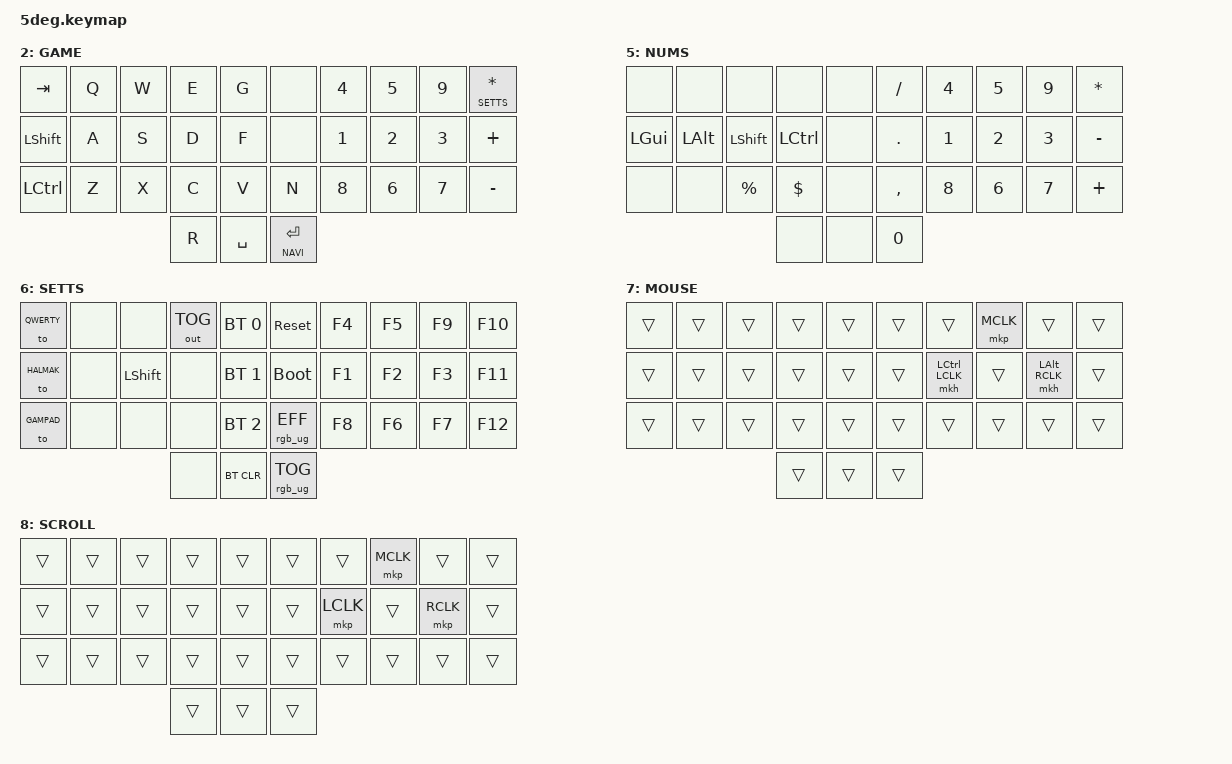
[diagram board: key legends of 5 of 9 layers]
/*
 * 5deg keymap — ported from little-wing
 *
 * Layers:
 *   0 = HALMAK (default)
 *   1 = QWERTY
 *   2 = GAMPAD
 *   3 = NAVI   (symbols + navigation)
 *   4 = EDIT   (undo/cut/copy/paste, brackets, alt-tab)
 *   5 = NUMS   (numpad grid)
 *   6 = SETTS  (layout select, BT, F-keys, system)
 *   7 = ALTAB  (alt-tab hold mode)
 *   8 = MOUSE  (auto-activated by trackball, mouse clicks)
 *   9 = SCROLL (trackball → scroll wheel)
 *
 * Home-row mods use QWERTY_MOD_MACRO so that holding a mod on
 * the HALMAK layer sends shortcuts in QWERTY positions (Ctrl+C etc).
 *
 * Key positions:
 *
 * LEFT (pinky → inner)         RIGHT (inner → pinky)
 * ┌────┬────┬────┬────┬────┐   ┌────┬────┬────┬────┬────┐
 * │ 0  │ 1  │ 2  │ 3  │ 4  │   │ 5  │ 6  │ 7  │ 8  │ 9  │
 * ├────┼────┼────┼────┼────┤   ├────┼────┼────┼────┼────┤
 * │ 10 │ 11 │ 12 │ 13 │ 14 │   │ 15 │ 16 │ 17 │ 18 │ 19 │
 * ├────┼────┼────┼────┼────┤   ├────┼────┼────┼────┼────┤
 * │ 20 │ 21 │ 22 │ 23 │ 24 │   │ 25 │ 26 │ 27 │ 28 │ 29 │
 * └────┴────┴──┬─┴──┬─┴────┘   └────┴─┬──┴────┴────┴────┘
 *              │ 30 │ 31 │        │ 32 │
 *              └────┴────┘        └────┘
 */

#include <behaviors.dtsi>
#include <dt-bindings/zmk/keys.h>
#include <dt-bindings/zmk/bt.h>
#include <dt-bindings/zmk/outputs.h>
#include <dt-bindings/zmk/mouse.h>
#include <dt-bindings/zmk/input_transform.h>
#include <dt-bindings/zmk/rgb.h>
#include <dt-bindings/zmk/ext_power.h>

&lt {
	flavor = "hold-preferred";
    tapping-term-ms = <200>;
    quick-tap-ms = <100>;
    require-prior-idle-ms = <150>;
};

/* Per-hand position lists for hold-trigger-key-positions on home-row mods.
 * A home-row mod only resolves to HOLD when an OPPOSITE-hand key triggers it,
 * which eliminates same-hand rolling misfires (e.g. typing "th" briefly
 * sharing two HRM keys on the left should never fire a modifier). */
#define LEFT_HAND  0 1 2 3 4 10 11 12 13 14 20 21 22 23 24 30 31
#define RIGHT_HAND 5 6 7 8 9 15 16 17 18 19 25 26 27 28 29 32
#define RIGHT_HAND_CTRL  5 6 7 8 9 15 16 17 18 19 25 26 27 28 29 32 /* one handed ctrl-q ctrl-a ctrl-s */ 0 10 11 

/* Per-finger HRM tapping terms (ms). Tuned from typing-hold-time
 * distribution: ~1.4-1.6× the p95 typing hold per finger so normal
 * typing rarely trips the hold-timer but chord still feels responsive.
 * Pinky drags more, so longer term; index is fastest, shortest term. */
#define HRM_TERM_PINKY  220
#define HRM_TERM_RING   200
#define HRM_TERM_MIDDLE 160   /* used by sht — can move independently */
#define HRM_TERM_INDEX  180

/* Quick-tap window: same across fingers per the retap data — slower
 * fingers don't double-tap faster, they just double-tap less often. */
#define HRM_QUICK_TAP   120

&caps_word {
	continue-list = <UNDER MINUS BSPC RSHFT LSHFT>;
};

#define HALMAK 0
#define QWERTY 1
#define GAMPAD 2
#define NAVI   3
#define EDIT   4
#define NUMS   5
#define SETTS  6
#define MOUSE  7
#define SCROLL 8

/* Home-row mod macro: hold activates QWERTY layer + modifier
 * so that keyboard shortcuts (Ctrl+C etc) use QWERTY positions
 * even when typing in HALMAK. */
#define QWERTY_MOD_MACRO(name, mod)            \
name: name##_macro {                           \
	compatible = "zmk,behavior-macro";         \
	#binding-cells = <0>;                      \
	wait-ms = <0>;                             \
    bindings                                   \
        = <&macro_press &mo QWERTY &kp mod>    \
        , <&macro_pause_for_release>           \
        , <&macro_release &mo QWERTY &kp mod>; \
};

/ {
    macros {
        QWERTY_MOD_MACRO(qalt, LALT)
        QWERTY_MOD_MACRO(qgui, LGUI)
        QWERTY_MOD_MACRO(qctl, LCTRL)

    };
};

#define HOME_ROW_MOD_TAP(name, macro, OPP_HAND, TERM) \
name: name##_mod_tap {                                \
    compatible = "zmk,behavior-hold-tap";             \
    #binding-cells = <2>;                             \
    flavor = "tap-preferred";                         \
    tapping-term-ms = <TERM>;                         \
    quick-tap-ms = <HRM_QUICK_TAP>;                   \
    hold-trigger-key-positions = <OPP_HAND>;          \
    require-prior-idle-ms = <100>;                    \
    bindings = <macro>, <&kp>;                        \
};

#define SHT_HT(name, OPP_HAND, TERM)                  \
name: name##_quick_hold_tap {                         \
    compatible = "zmk,behavior-hold-tap";             \
    #binding-cells = <2>;                             \
    flavor = "tap-preferred";                         \
    tapping-term-ms = <TERM>;                         \
    quick-tap-ms = <HRM_QUICK_TAP>;                   \
    hold-trigger-key-positions = <OPP_HAND>;          \
    require-prior-idle-ms = <80>;                     \
    bindings = <&kp>, <&kp>;                          \
};

/ {
    behaviors {
        /* Letter-LT: layer-tap on a key that is primarily a letter, not
         * a layer key. tap-preferred so fast rolls into D/J/O/P never
         * activate the layer; user must hold the full tapping-term to
         * intentionally enter the layer. */
        qlt: layer_tap_letter {
            compatible = "zmk,behavior-hold-tap";
            #binding-cells = <2>;
            flavor = "tap-preferred";
            tapping-term-ms = <300>;
            quick-tap-ms = <150>;
            bindings = <&mo>, <&kp>;
        };
    };
};

/ {
    behaviors {
        /* Left hand, inner→outer (HRML order: index, middle, ring, pinky) */
        HOME_ROW_MOD_TAP(ht_ctl_l, &qctl, RIGHT_HAND_CTRL, HRM_TERM_INDEX)   /* pos 13, T */
        SHT_HT          (sht_l,           RIGHT_HAND, HRM_TERM_MIDDLE) /* pos 12, N */
        HOME_ROW_MOD_TAP(ht_alt_l, &qalt, RIGHT_HAND, HRM_TERM_RING)   /* pos 11, H */
        HOME_ROW_MOD_TAP(ht_gui_l, &qgui, RIGHT_HAND, HRM_TERM_PINKY)  /* pos 10, S */

        /* Right hand, inner→outer (HRMR order: index, middle, ring, pinky) */
        HOME_ROW_MOD_TAP(ht_ctl_r, &qctl, LEFT_HAND,  HRM_TERM_INDEX)  /* pos 15, A */
        SHT_HT          (sht_r,           LEFT_HAND,  HRM_TERM_MIDDLE) /* pos 16, E */
        HOME_ROW_MOD_TAP(ht_alt_r, &qalt, LEFT_HAND,  HRM_TERM_RING)   /* pos 17, O */
        HOME_ROW_MOD_TAP(ht_gui_r, &qgui, LEFT_HAND,  HRM_TERM_PINKY)  /* pos 18, I */
        alt_tab: alt_tab {
            compatible = "zmk,behavior-alt-tab";
            #binding-cells = <2>;
            hold-ms = <10>;
        };
        mkh: mkh {
            compatible = "zmk,behavior-mkh";
            #binding-cells = <2>;
            flavor = "balanced";
            tapping-term-ms = <250>;
            prior-motion-ms = <400>;
            bindings = <&kp>, <&mkp>;
        };
    };
};

#define HRML(k1,k2,k3,k4) &ht_gui_l 0 k1  &ht_alt_l 0 k2  &sht_l LSHFT k3  &ht_ctl_l 0 k4
#define HRMR(k1,k2,k3,k4) &ht_ctl_r 0 k1  &sht_r RSHFT k2  &ht_alt_r 0 k3  &ht_gui_r 0 k4

/* Vertical-column combos for Ctrl+Z/X/C/V — only active on the EDIT
 * layer, parallel to the HRML(LC(Z), LC(X), LC(C), LC(V)) tap path.
 * Press both keys in the same left-hand finger column simultaneously
 * (pinky=Z, ring=X, middle=C, index=V — mirrors QWERTY bottom row).
 * Combo fires on press, so no HRM tap-on-release decision delay. */
/ {
    combos {
        compatible = "zmk,combos";

        combo_ctrl_z {
            timeout-ms = <50>;
            key-positions = <10 20>;   /* L pinky home + bottom */
            bindings = <&kp LC(Z)>;
            layers = <EDIT>;
        };
        combo_ctrl_x {
            timeout-ms = <50>;
            key-positions = <11 21>;   /* L ring home + bottom */
            bindings = <&kp LC(X)>;
            layers = <EDIT>;
        };
        combo_ctrl_c {
            timeout-ms = <50>;
            key-positions = <12 22>;   /* L middle home + bottom */
            bindings = <&kp LC(C)>;
            layers = <EDIT>;
        };
        combo_ctrl_v {
            timeout-ms = <50>;
            key-positions = <13 23>;   /* L index home + bottom */
            bindings = <&kp LC(V)>;
            layers = <EDIT>;
        };
    };
};

/ {
    /* Mouse layer processor — properties */
    zip_mouse_layer {
        require-prior-idle-ms = <1200>;
        activation-threshold = <10>;
        activation-window-ms = <200>;
        activation-event-min = <3>;
        double-click-window-ms = <300>;
        active-layers = <HALMAK QWERTY EDIT>;
        button-positions = <7 16 18>;   /* MCLK, LCLK, RCLK on MOUSE layer */
    };

    /* Trackball input processor pipeline — default + layer overrides.
     * zip_pmw3610_unpack_xy must run FIRST so the packed-XY events from
     * the trackball half are split into REL_X/REL_Y before any other
     * processor inspects them. Pass-through when packing is disabled. */
    trackball_listener {
        input-processors =
            <&zip_pmw3610_unpack_xy>,
            <&zip_spike_filter 6>,
            <&zip_response_curve 6>,
            <&zip_xy_scaler 2 3>,
            <&zip_mouse_layer MOUSE 1200>;

        scroll {
            layers = <SCROLL>;
            input-processors =
                <&zip_pmw3610_unpack_xy>,
                <&zip_spike_filter 6>,
                <&zip_xy_scaler 1 80>,
                <&zip_xy_to_scroll_mapper>,
                <&zip_scroll_transform INPUT_TRANSFORM_Y_INVERT>;
        };

        gaming {
            layers = <GAMPAD>;
            input-processors =
                <&zip_pmw3610_unpack_xy>,
                <&zip_spike_filter 6>,
                <&zip_response_curve 4>,
                <&zip_xy_scaler 2 3>;
        };
    };


    keymap {
        compatible = "zmk,keymap";

        halmak_layer {
            display-name = "HALMAK";
            bindings = <
                &kp W      &kp L      &kp R      &kp B      &kp Z          &kp SEMI   &kp Q      &kp U  &qlt SCROLL D &qlt SETTS J
                HRML(S,        H,         N,         T)     &kp COMMA      &kp DOT   HRMR(A,         E,         O,         I)
                &kp F      &kp M      &kp V      &kp C      &kp FSLH       &kp G      &kp P      &kp X      &kp K      &kp Y
                                            &lt NUMS BSPC  &lt EDIT SPACE &lt NAVI ENTER
            >;
        };

        qwerty_layer {
            display-name = "QWERTY";
            bindings = <
                &kp Q      &kp W      &kp E      &kp R      &kp T          &kp Y      &kp U      &kp I   &qlt SCROLL O &qlt SETTS P
                HRML(A,        S,         D,         F)     &kp G          &kp H     HRMR(J,         K,         L,         SEMI)
                &kp Z      &kp X      &kp C      &kp V      &kp B          &kp N      &kp M      &kp COMMA  &kp DOT    &kp FSLH
                                            &lt NUMS BSPC  &lt EDIT SPACE &lt NAVI ENTER
            >;
        };

        gamepad_layer {
            display-name = "GAME";
            bindings = <
                &kp TAB    &kp Q      &kp W      &kp E      &kp G          &none      &kp N4     &kp N5     &kp N9    &qlt SETTS STAR
                &kp LSHFT  &kp A      &kp S      &kp D      &kp F          &none      &kp N1     &kp N2     &kp N3     &kp PLUS
                &kp LCTRL  &kp Z      &kp X      &kp C      &kp V          &kp N      &kp N8     &kp N6     &kp N7     &kp MINUS
                                                 &kp R      &kp SPACE      &lt NAVI ENTER
            >;
        };

        navigation_layer {
            display-name = "NAVI";
            bindings = <
                &kp CARET  &kp LBRC   &kp ASTRK  &kp RBRC   &none          &none   &kp LC(LEFT)  &kp UP &kp LC(RIGHT) &kp PG_UP
                HRML(EXCL,     LPAR,      HASH,      RPAR)  &none          &none      &kp LEFT   &kp DOWN   &kp RIGHT  &kp PG_DN
                &kp QMARK  &kp AT     &kp PRCNT  &kp DLLR   &none          &none      &none      &none      &none      &none
                                                 &kp DEL    &kp UNDER      &none
            >;
        };

        edit_layer {
            display-name = "EDIT";
            bindings = <
                &kp TAB    &alt_tab LCTRL TAB  &kp LC(TILDE) &kp ESC  &none    &none      &kp LBKT   &kp MINUS  &kp RBKT   &kp GRAVE
              HRML(LC(Z),  LC(X),     LC(C),     LC(V))     &kp LC(LS(Z))  &kp TILDE HRMR(LT,        EQUAL,     GT,        SQT)
                &none      &none      &none      &none      &none          &none      &kp FSLH   &kp PIPE   &kp BSLH   &kp DQT
                                                 &none      &none          &kp AMPS
            >;
        };

        nums_layer {
            display-name = "NUMS";
            bindings = <
                &none      &none      &none      &none      &none          &kp FSLH   &kp N4     &kp N5     &kp N9     &kp STAR
                &kp LGUI   &kp LALT   &kp LSHFT  &kp LCTRL  &none          &kp DOT    &kp N1     &kp N2     &kp N3     &kp MINUS
                &none      &none      &kp PRCNT  &kp DLLR   &none          &kp COMMA  &kp N8     &kp N6     &kp N7     &kp PLUS
                                                 &none      &none          &kp N0
            >;
        };

        settings_layer {
            display-name = "SETTS";
            bindings = <
                &to QWERTY &none      &none    &out OUT_TOG &bt BT_SEL 0   &sys_reset        &kp F4          &kp F5          &kp F9     &kp F10
                &to HALMAK &none      &kp LSHFT  &none      &bt BT_SEL 1   &bootloader       &kp F1          &kp F2          &kp F3     &kp F11
                &to GAMPAD &none      &none      &none      &bt BT_SEL 2   &rgb_ug RGB_EFF   &kp F8          &kp F6          &kp F7     &kp F12
                                                 &none      &bt BT_CLR     &rgb_ug RGB_TOG
            >;
        };

        mouse_layer {
            display-name = "MOUSE";
            bindings = <
                &trans     &trans     &trans     &trans     &trans         &trans     &trans    &mkp MCLK     &trans     &trans
                &trans     &trans     &trans     &trans     &trans         &trans  &mkh LCTRL LCLK  &trans  &mkh LALT RCLK &trans
                &trans     &trans     &trans     &trans     &trans         &trans     &trans     &trans       &trans     &trans
                                                 &trans     &trans         &trans
            >;
        };

        scroll_layer {
            display-name = "SCROLL";
            bindings = <
                &trans     &trans     &trans     &trans     &trans         &trans     &trans     &mkp MCLK  &trans     &trans
                &trans     &trans     &trans     &trans     &trans         &trans     &mkp LCLK  &trans     &mkp RCLK  &trans
                &trans     &trans     &trans     &trans     &trans         &trans     &trans     &trans     &trans     &trans
                                                 &trans     &trans         &trans
            >;
        };
    };
};

